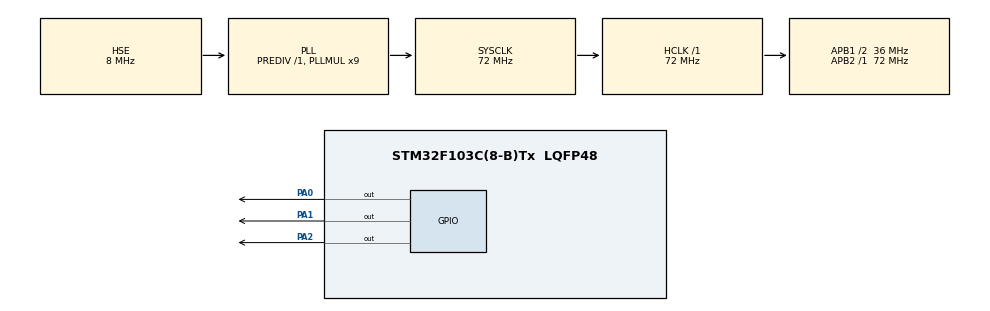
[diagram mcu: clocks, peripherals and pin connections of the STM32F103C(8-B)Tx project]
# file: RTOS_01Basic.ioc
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FREERTOS.Tasks01=defaultTask,0,128,StartDefaultTask,Default,NULL,Dynamic,NULL,NULL;LED1_Task,0,128,StartLED1,Default,NULL,Dynamic,NULL,NULL;LED2_Task,0,128,StartLED2,Default,NULL,Dynamic,NULL,NULL;LED3_Task,0,128,StartLED3,Default,NULL,Dynamic,NULL,NULL
Mcu.Family=STM32F1
Mcu.Name=STM32F103C(8-B)Tx
Mcu.Package=LQFP48
NVIC.PriorityGroup=NVIC_PRIORITYGROUP_4
NVIC.TIM4_IRQn=true\:15\:0\:false\:false\:true\:false\:false\:true\:true
NVIC.TimeBase=TIM4_IRQn
NVIC.TimeBaseIP=TIM4
PA0-WKUP.Signal=GPIO_Output
PA1.Signal=GPIO_Output
PA13.Mode=Serial_Wire
PA13.Signal=SYS_JTMS-SWDIO
PA14.Mode=Serial_Wire
PA14.Signal=SYS_JTCK-SWCLK
PA2.Signal=GPIO_Output
PD0-OSC_IN.Mode=HSE-External-Oscillator
PD0-OSC_IN.Signal=RCC_OSC_IN
PD1-OSC_OUT.Mode=HSE-External-Oscillator
PD1-OSC_OUT.Signal=RCC_OSC_OUT
ProjectManager.HeapSize=0x200
ProjectManager.StackSize=0x400
ProjectManager.TargetToolchain=MDK-ARM V5.32
RCC.AHBFreq_Value=72000000
RCC.APB1CLKDivider=RCC_HCLK_DIV2
RCC.APB1Freq_Value=36000000
RCC.APB1TimFreq_Value=72000000
RCC.APB2Freq_Value=72000000
RCC.APB2TimFreq_Value=72000000
RCC.HCLKFreq_Value=72000000
RCC.PLLMUL=RCC_PLL_MUL9
RCC.PLLSourceVirtual=RCC_PLLSOURCE_HSE
RCC.SYSCLKFreq_VALUE=72000000
RCC.SYSCLKSource=RCC_SYSCLKSOURCE_PLLCLK
RCC.USBFreq_Value=72000000
VP_FREERTOS_VS_CMSIS_V1.Mode=CMSIS_V1
VP_SYS_VS_tim4.Mode=TIM4
board=custom

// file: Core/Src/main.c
/* USER CODE BEGIN Header */
/**
  ******************************************************************************
  * @file           : main.c
  * @brief          : Main program body
  ******************************************************************************
  * @attention
  *
  * Copyright (c) 2026 STMicroelectronics.
  * All rights reserved.
  *
  * This software is licensed under terms that can be found in the LICENSE file
  * in the root directory of this software component.
  * If no LICENSE file comes with this software, it is provided AS-IS.
  *
  ******************************************************************************
  */
/* USER CODE END Header */
#include "main.h"
#include "cmsis_os.h"

osThreadId defaultTaskHandle;
osThreadId LED1_TaskHandle;
osThreadId LED2_TaskHandle;
osThreadId LED3_TaskHandle;

void SystemClock_Config(void);
static void MX_GPIO_Init(void);
void StartDefaultTask(void const * argument);
void StartLED1(void const * argument);
void StartLED2(void const * argument);
void StartLED3(void const * argument);

int main(void)
{

  /* MCU Configuration--------------------------------------------------------*/

  /* Reset of all peripherals, Initializes the Flash interface and the Systick. */
  HAL_Init();

  /* Configure the system clock */
  SystemClock_Config();

  /* Initialize all configured peripherals */
  MX_GPIO_Init();

  /* Create the thread(s) */
  /* definition and creation of defaultTask */
  osThreadDef(defaultTask, StartDefaultTask, osPriorityNormal, 0, 128);
  defaultTaskHandle = osThreadCreate(osThread(defaultTask), NULL);

  /* definition and creation of LED1_Task */
  osThreadDef(LED1_Task, StartLED1, osPriorityNormal, 0, 128);
  LED1_TaskHandle = osThreadCreate(osThread(LED1_Task), NULL);

  /* definition and creation of LED2_Task */
  osThreadDef(LED2_Task, StartLED2, osPriorityNormal, 0, 128);
  LED2_TaskHandle = osThreadCreate(osThread(LED2_Task), NULL);

  /* definition and creation of LED3_Task */
  osThreadDef(LED3_Task, StartLED3, osPriorityNormal, 0, 128);
  LED3_TaskHandle = osThreadCreate(osThread(LED3_Task), NULL);

  /* Start scheduler */
  osKernelStart();

  /* We should never get here as control is now taken by the scheduler */

  /* Infinite loop */
  while (1)
  {

  }
}

void SystemClock_Config(void)
{
  RCC_OscInitTypeDef RCC_OscInitStruct = {0};
  RCC_ClkInitTypeDef RCC_ClkInitStruct = {0};

  /** Initializes the RCC Oscillators according to the specified parameters
  * in the RCC_OscInitTypeDef structure.
  */
  RCC_OscInitStruct.OscillatorType = RCC_OSCILLATORTYPE_HSE;
  RCC_OscInitStruct.HSEState = RCC_HSE_ON;
  RCC_OscInitStruct.HSEPredivValue = RCC_HSE_PREDIV_DIV1;
  RCC_OscInitStruct.HSIState = RCC_HSI_ON;
  RCC_OscInitStruct.PLL.PLLState = RCC_PLL_ON;
  RCC_OscInitStruct.PLL.PLLSource = RCC_PLLSOURCE_HSE;
  RCC_OscInitStruct.PLL.PLLMUL = RCC_PLL_MUL9;
  if (HAL_RCC_OscConfig(&RCC_OscInitStruct) != HAL_OK)
  {
    Error_Handler();
  }

  /** Initializes the CPU, AHB and APB buses clocks
  */
  RCC_ClkInitStruct.ClockType = RCC_CLOCKTYPE_HCLK|RCC_CLOCKTYPE_SYSCLK
                              |RCC_CLOCKTYPE_PCLK1|RCC_CLOCKTYPE_PCLK2;
  RCC_ClkInitStruct.SYSCLKSource = RCC_SYSCLKSOURCE_PLLCLK;
  RCC_ClkInitStruct.AHBCLKDivider = RCC_SYSCLK_DIV1;
  RCC_ClkInitStruct.APB1CLKDivider = RCC_HCLK_DIV2;
  RCC_ClkInitStruct.APB2CLKDivider = RCC_HCLK_DIV1;

  if (HAL_RCC_ClockConfig(&RCC_ClkInitStruct, FLASH_LATENCY_2) != HAL_OK)
  {
    Error_Handler();
  }
}

static void MX_GPIO_Init(void)
{
  GPIO_InitTypeDef GPIO_InitStruct = {0};

  /* GPIO Ports Clock Enable */
  __HAL_RCC_GPIOD_CLK_ENABLE();
  __HAL_RCC_GPIOA_CLK_ENABLE();

  /*Configure GPIO pin Output Level */
  HAL_GPIO_WritePin(GPIOA, GPIO_PIN_0|GPIO_PIN_1|GPIO_PIN_2, GPIO_PIN_RESET);

  /*Configure GPIO pins : PA0 PA1 PA2 */
  GPIO_InitStruct.Pin = GPIO_PIN_0|GPIO_PIN_1|GPIO_PIN_2;
  GPIO_InitStruct.Mode = GPIO_MODE_OUTPUT_PP;
  GPIO_InitStruct.Pull = GPIO_NOPULL;
  GPIO_InitStruct.Speed = GPIO_SPEED_FREQ_LOW;
  HAL_GPIO_Init(GPIOA, &GPIO_InitStruct);

}

/* USER CODE BEGIN 4 */
void LED_Blink(GPIO_TypeDef *GPIOx, uint16_t GPIO_Pin, float frequency);
void LED_Blink(GPIO_TypeDef *GPIOx, uint16_t GPIO_Pin, float frequency)
{
    uint32_t delay_ms;

    delay_ms = (uint32_t)(1000.0f /(2.0f * frequency));

    HAL_GPIO_TogglePin(GPIOx, GPIO_Pin);

    osDelay(delay_ms);
}
/* USER CODE END 4 */

void StartDefaultTask(void const * argument)
{
  for(;;)
  {
    osDelay(1);
  }
}

void StartLED1(void const * argument)
{
  /* USER CODE BEGIN StartLED1 */
  /* Infinite loop */
  for(;;)
  {
    LED_Blink(GPIOA, GPIO_PIN_0, 0.1f);
  }
  /* USER CODE END StartLED1 */
}

void StartLED2(void const * argument)
{
  /* USER CODE BEGIN StartLED2 */
  /* Infinite loop */
  for(;;)
  {
    LED_Blink(GPIOA, GPIO_PIN_1, 1.0f);
  }
  /* USER CODE END StartLED2 */
}

void StartLED3(void const * argument)
{
  /* USER CODE BEGIN StartLED3 */
  /* Infinite loop */
  for(;;)
  {
    LED_Blink(GPIOA, GPIO_PIN_2, 10.0f);
  }
  /* USER CODE END StartLED3 */
}

void HAL_TIM_PeriodElapsedCallback(TIM_HandleTypeDef *htim)
{
  if (htim->Instance == TIM4)
  {
    HAL_IncTick();
  }
}

void Error_Handler(void)
{
  __disable_irq();
  while (1)
  {
  }
}

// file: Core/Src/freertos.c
/* USER CODE BEGIN Header */
/**
  ******************************************************************************
  * File Name          : freertos.c
  * Description        : Code for freertos applications
  ******************************************************************************
  * @attention
  *
  * Copyright (c) 2026 STMicroelectronics.
  * All rights reserved.
  *
  * This software is licensed under terms that can be found in the LICENSE file
  * in the root directory of this software component.
  * If no LICENSE file comes with this software, it is provided AS-IS.
  *
  ******************************************************************************
  */
/* USER CODE END Header */

#include "FreeRTOS.h"
#include "task.h"
#include "main.h"
#include "cmsis_os.h"

/* GetIdleTaskMemory prototype (linked to static allocation support) */
void vApplicationGetIdleTaskMemory( StaticTask_t **ppxIdleTaskTCBBuffer, StackType_t **ppxIdleTaskStackBuffer, uint32_t *pulIdleTaskStackSize );

/* USER CODE BEGIN GET_IDLE_TASK_MEMORY */
static StaticTask_t xIdleTaskTCBBuffer;
static StackType_t xIdleStack[configMINIMAL_STACK_SIZE];

void vApplicationGetIdleTaskMemory( StaticTask_t **ppxIdleTaskTCBBuffer, StackType_t **ppxIdleTaskStackBuffer, uint32_t *pulIdleTaskStackSize )
{
  *ppxIdleTaskTCBBuffer = &xIdleTaskTCBBuffer;
  *ppxIdleTaskStackBuffer = &xIdleStack[0];
  *pulIdleTaskStackSize = configMINIMAL_STACK_SIZE;
  /* place for user code */
}
/* USER CODE END GET_IDLE_TASK_MEMORY */
